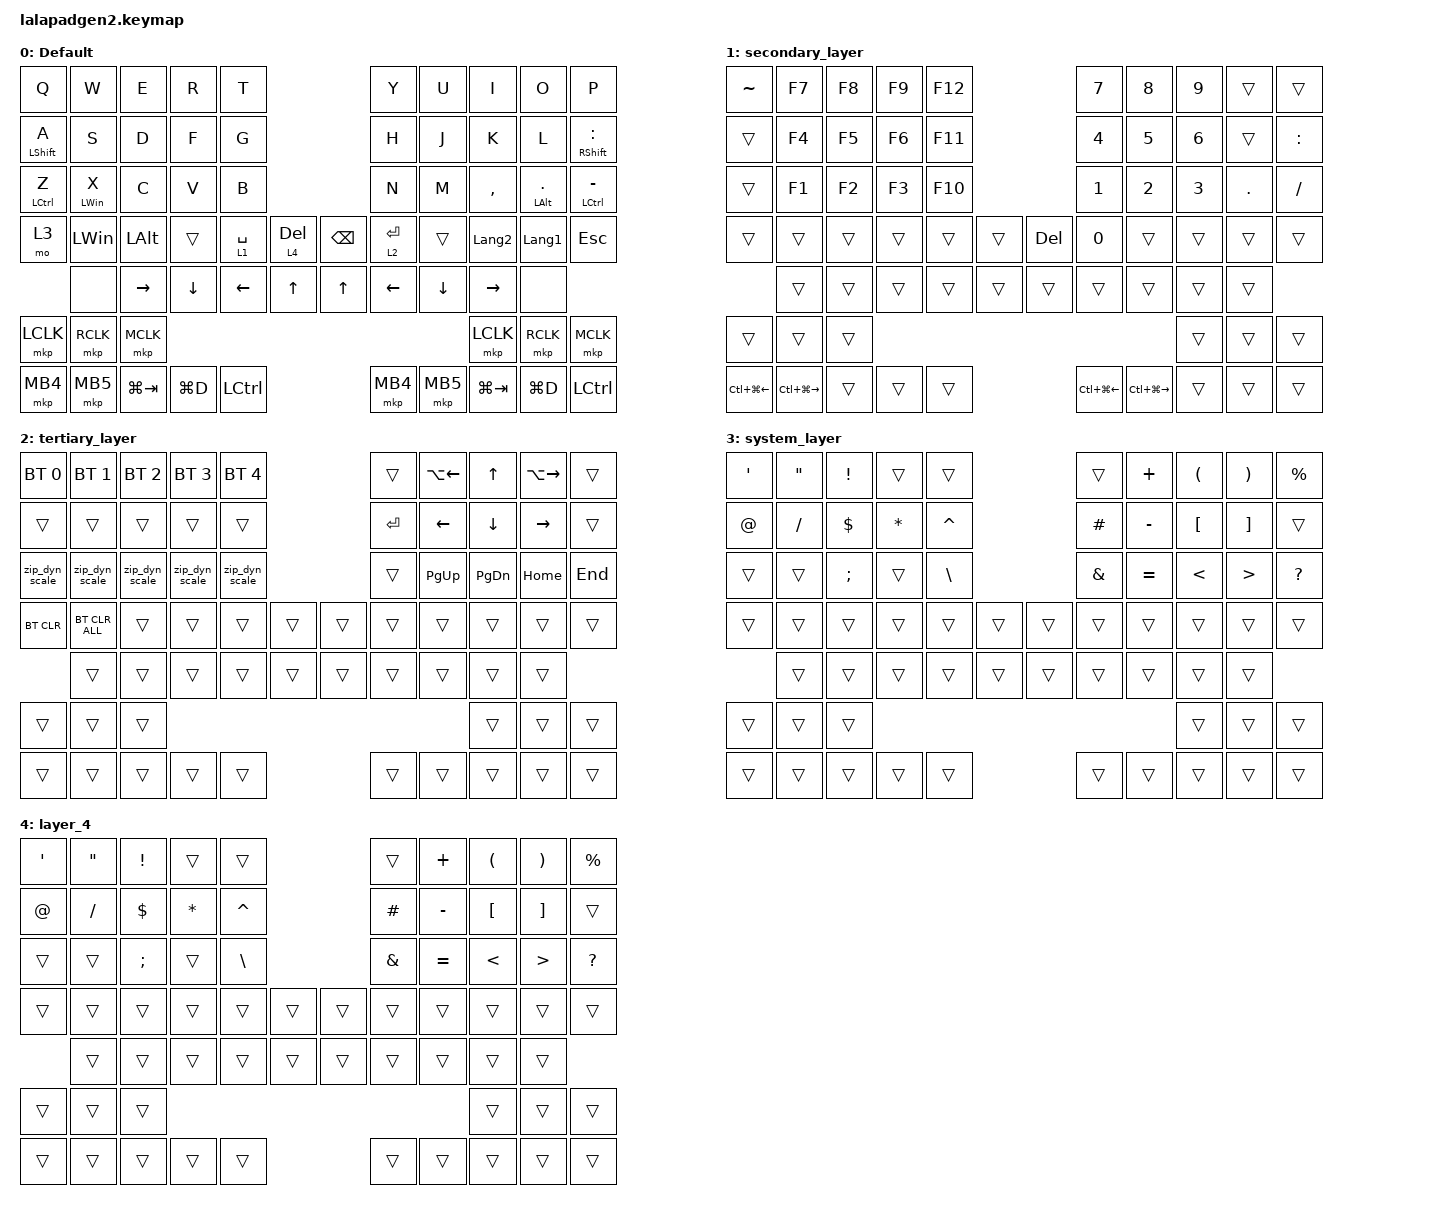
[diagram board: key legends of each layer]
#include <input/processors.dtsi>
#include <dt-bindings/zmk/zip_dynamic_scale.h>
#include <behaviors.dtsi>
#include <dt-bindings/zmk/bt.h>
#include <dt-bindings/zmk/keys.h>
#include <dt-bindings/zmk/pointing.h>

#define DEFAULT_LAYER   0
#define SECONDARY_LAYER 1
#define TERTIARY_LAYER  2
#define SYSTEM_LAYER    3

&mt { quick-tap-ms = <200>; };

&lt { quick-tap-ms = <200>; };

/ {
    behaviors {
        zip_dyn_scale: zip_dyn_scale {
            compatible = "zmk,behavior-zip-dynamic-scale";
            #binding-cells = <2>;
        };

        zip_dyn_scale_set: zip_dyn_scale_set {
            compatible = "zmk,behavior-zip-dynamic-scale-set";
            #binding-cells = <2>;
        };

        mt2: mod_tap2 {
            compatible = "zmk,behavior-hold-tap";
            #binding-cells = <2>;
            flavor = "tap-preferred";
            tapping-term-ms = <200>;
            quick-tap-ms = <200>;
            require-prior-idle-ms = <125>;
            bindings = <&kp>, <&kp>;
        };

        tap_dance_layer_1and2: tap_dance_layer_1and2 {
            compatible = "zmk,behavior-tap-dance";
            label = "td_mo12";
            #binding-cells = <0>;
            bindings = <&mo 1>, <&mo 2>;
        };
    };

    combos {
        compatible = "zmk,combos";

        CONBO_ESC {
            bindings = <&kp ESCAPE>;
            key-positions = <1 2>;
        };

        COMBO_TAB {
            bindings = <&kp TAB>;
            key-positions = <1 3>;
        };

        COMBO_SHIFTTAB {
            bindings = <&kp LS(TAB)>;
            key-positions = <3 2 1>;
        };

        COMBO_EISU {
            bindings = <&kp LANG2>;
            key-positions = <22 21>;
        };

        COMBO_KANA {
            bindings = <&kp LANGUAGE_1>;
            key-positions = <27 28>;
        };

        COMBO_BACKSPACE {
            bindings = <&kp BACKSPACE>;
            key-positions = <13 12>;
        };
    };

    keymap {
        compatible = "zmk,keymap";

        DEFAULT_LAYER {
            display-name = "Default";
            bindings = <
&kp Q                &kp W            &kp E         &kp R      &kp T                                     &kp Y        &kp U     &kp I           &kp O                 &kp P
&mt2 LEFT_SHIFT A    &kp S            &kp D         &kp F      &kp G                                     &kp H        &kp J     &kp K           &kp L                 &mt2 RIGHT_SHIFT COLON
&mt2 LEFT_CONTROL Z  &mt2 LEFT_WIN X  &kp C         &kp V      &kp B                                     &kp N        &kp M     &kp COMMA       &mt2 LEFT_ALT PERIOD  &mt2 LEFT_CONTROL MINUS
&mo 3                &kp LWIN         &kp LEFT_ALT  &trans     &lt 1 SPACE  &lt 4 DELETE  &kp BACKSPACE  &lt 2 ENTER  &trans    &kp LANGUAGE_2  &kp LANGUAGE_1        &kp ESC
                     &none            &kp RIGHT     &kp DOWN   &kp LEFT     &kp UP        &kp UP         &kp LEFT     &kp DOWN  &kp RIGHT       &none
&mkp LCLK            &mkp RCLK        &mkp MCLK                                                                                 &mkp LCLK       &mkp RCLK             &mkp MCLK
&mkp MB4             &mkp MB5         &kp LG(TAB)   &kp LG(D)  &kp LCTRL                                 &mkp MB4     &mkp MB5  &kp LG(TAB)     &kp LG(D)             &kp LCTRL
            >;
        };

        SECONDARY_LAYER {
            display-name = "secondary_layer";
            bindings = <
&kp TILDE         &kp F7             &kp F8  &kp F9  &kp F12                   &kp N7            &kp N8             &kp N9        &trans   &trans
&trans            &kp F4             &kp F5  &kp F6  &kp F11                   &kp NUMBER_4      &kp N5             &kp NUMBER_6  &trans   &kp COLON
&trans            &kp F1             &kp F2  &kp F3  &kp F10                   &kp NUMBER_1      &kp NUMBER_2       &kp NUMBER_3  &kp DOT  &kp SLASH
&trans            &trans             &trans  &trans  &trans   &trans  &kp DEL  &kp N0            &trans             &trans        &trans   &trans
                  &trans             &trans  &trans  &trans   &trans  &trans   &trans            &trans             &trans        &trans
&trans            &trans             &trans                                                                         &trans        &trans   &trans
&kp LC(LG(LEFT))  &kp LC(LG(RIGHT))  &trans  &trans  &trans                    &kp LC(LG(LEFT))  &kp LC(LG(RIGHT))  &trans        &trans   &trans
            >;
        };

        TERTIARY_LAYER {
            display-name = "tertiary_layer";
            bindings = <
&bt BT_SEL 0    &bt BT_SEL 1    &bt BT_SEL 2    &bt BT_SEL 3    &bt BT_SEL 4                    &trans     &kp LA(LEFT_ARROW)  &kp UP_ARROW    &kp LA(RIGHT_ARROW)  &trans
&trans          &trans          &trans          &trans          &trans                          &kp ENTER  &kp LEFT            &kp DOWN_ARROW  &kp RIGHT            &trans
&zip_dyn_scale  &zip_dyn_scale  &zip_dyn_scale  &zip_dyn_scale  &zip_dyn_scale                  &trans     &kp PAGE_UP         &kp PAGE_DOWN   &kp HOME             &kp END
&bt BT_CLR      &bt BT_CLR_ALL  &trans          &trans          &trans          &trans  &trans  &trans     &trans              &trans          &trans               &trans
                &trans          &trans          &trans          &trans          &trans  &trans  &trans     &trans              &trans          &trans
&trans          &trans          &trans                                                                                         &trans          &trans               &trans
&trans          &trans          &trans          &trans          &trans                          &trans     &trans              &trans          &trans               &trans
            >;
        };

        SYSTEM_LAYER {
            display-name = "system_layer";
            bindings = <
&kp SINGLE_QUOTE  &kp DOUBLE_QUOTES  &kp EXCL       &trans     &trans                         &trans         &kp PLUS   &kp LEFT_PARENTHESIS  &kp RIGHT_PARENTHESIS  &kp PERCENT
&kp AT_SIGN       &kp SLASH          &kp DOLLAR     &kp ASTRK  &kp CARET                      &kp HASH       &kp MINUS  &kp LEFT_BRACKET      &kp RIGHT_BRACKET      &trans
&trans            &trans             &kp SEMICOLON  &trans     &kp BACKSLASH                  &kp AMPERSAND  &kp EQUAL  &kp LESS_THAN         &kp GREATER_THAN       &kp QUESTION
&trans            &trans             &trans         &trans     &trans         &trans  &trans  &trans         &trans     &trans                &trans                 &trans
                  &trans             &trans         &trans     &trans         &trans  &trans  &trans         &trans     &trans                &trans
&trans            &trans             &trans                                                                             &trans                &trans                 &trans
&trans            &trans             &trans         &trans     &trans                         &trans         &trans     &trans                &trans                 &trans
            >;
        };

        layer_4 {
            bindings = <
&kp SINGLE_QUOTE  &kp DOUBLE_QUOTES  &kp EXCLAMATION  &trans     &trans                         &trans         &kp PLUS   &kp LEFT_PARENTHESIS  &kp RIGHT_PARENTHESIS  &kp PERCENT
&kp AT_SIGN       &kp SLASH          &kp DOLLAR       &kp ASTRK  &kp CARET                      &kp HASH       &kp MINUS  &kp LEFT_BRACKET      &kp RIGHT_BRACKET      &trans
&trans            &trans             &kp SEMICOLON    &trans     &kp BACKSLASH                  &kp AMPERSAND  &kp EQUAL  &kp LESS_THAN         &kp GREATER_THAN       &kp QUESTION
&trans            &trans             &trans           &trans     &trans         &trans  &trans  &trans         &trans     &trans                &trans                 &trans
                  &trans             &trans           &trans     &trans         &trans  &trans  &trans         &trans     &trans                &trans
&trans            &trans             &trans                                                                               &trans                &trans                 &trans
&trans            &trans             &trans           &trans     &trans                         &trans         &trans     &trans                &trans                 &trans
            >;
        };
    };

    conditional_layers {
        compatible = "zmk,conditional-layers";

        Cond_Syslayer {
            if-layers = <1 2>;
            then-layer = <3>;
        };
    };
};
